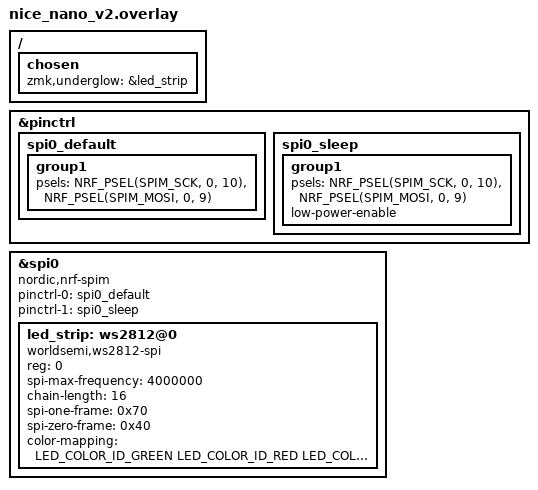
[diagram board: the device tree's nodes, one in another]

/**
 * Generated by Shield Wizard for ZMK
 * Applies to shield "parangklithik_left" with board "nice_nano_v2" only
 */

//
// ======== spi0 ========
//

// pin control for spi0
// - SCK on D16
// - MOSI on D10
&pinctrl {
    /* configuration for spi0 device, default state */
    spi0_default: spi0_default {
        group1 {
            psels = <NRF_PSEL(SPIM_SCK, 0, 10)>,
                    <NRF_PSEL(SPIM_MOSI, 0, 9)>;
        };
    };
    /* configuration for spi0 device, sleep state */
    spi0_sleep: spi0_sleep {
        group1 {
            psels = <NRF_PSEL(SPIM_SCK, 0, 10)>,
                    <NRF_PSEL(SPIM_MOSI, 0, 9)>;
            low-power-enable;
        };
    };
};
&spi0 {
  compatible = "nordic,nrf-spim";
  status = "okay";
  pinctrl-0 = <&spi0_default>;
  pinctrl-1 = <&spi0_sleep>;
  pinctrl-names = "default", "sleep";
};

// devices on spi0

#include <dt-bindings/led/led.h>
&spi0 {
    led_strip: ws2812@0 {
        compatible = "worldsemi,ws2812-spi";
        reg = <0>;
        spi-max-frequency = <4000000>;

        chain-length = <16>;
        spi-one-frame = <0x70>;
        spi-zero-frame = <0x40>;
        color-mapping = <LED_COLOR_ID_GREEN
                         LED_COLOR_ID_RED
                         LED_COLOR_ID_BLUE>;
    };
};
/ {
    chosen {
        zmk,underglow = &led_strip;
    };
};
